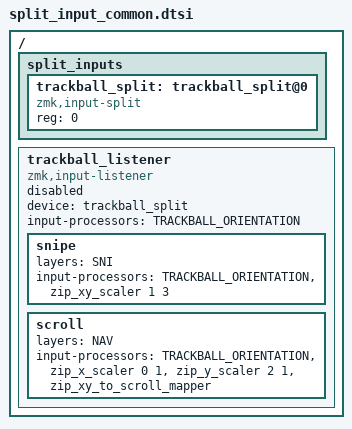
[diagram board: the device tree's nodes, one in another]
#include <dt-bindings/zmk/input_transform.h>
#include <input/processors.dtsi>

/* * PHYSICAL ORIENTATION MACRO
 * Change this one line to affect every layer (Movement, Snipe, Scroll)
 */
#define TRACKBALL_ORIENTATION \
    <&zip_xy_transform (INPUT_TRANSFORM_X_INVERT | INPUT_TRANSFORM_Y_INVERT | INPUT_TRANSFORM_XY_SWAP)>

/ {
  split_inputs {
    #address-cells = <1>;
    #size-cells = <0>;

    trackball_split: trackball_split@0 {
      compatible = "zmk,input-split";
      reg = <0>;
    };
  };

  trackball_listener: trackball_listener {
    compatible = "zmk,input-listener";
    status = "disabled";
    device = <&trackball_split>;

    /* BASE MOVEMENT */
    input-processors = <TRACKBALL_ORIENTATION>;

    /* SNIPE LAYER: Slows down movement for precision */
    snipe {
      layers = <SNI>;
      input-processors =
        <TRACKBALL_ORIENTATION>,
        <&zip_xy_scaler 1 3>; // 1/3 speed
    };

    /* SCROLL LAYER: Converts ball movement to scroll wheels */
    scroll {
      layers = <NAV>;
      input-processors =
        <TRACKBALL_ORIENTATION>, // Keep orientation consistent
        <&zip_x_scaler 0 1>,     // Disable horizontal scrolling
        <&zip_y_scaler 2 1>,     // Adjust vertical scroll sensitivity
        <&zip_xy_to_scroll_mapper>;
    };
  };
};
